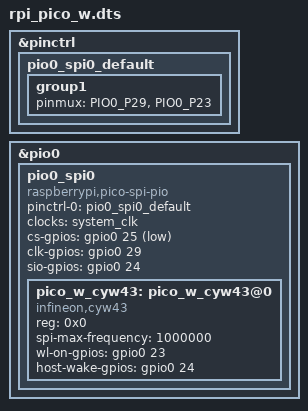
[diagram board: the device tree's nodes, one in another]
/*
 * Copyright (c) 2023 Dave Rensberger - Beechwoods Software
 *
 * SPDX-License-Identifier: Apache-2.0
 */

/dts-v1/;

#include "rpi_pico-common.dtsi"

&pinctrl {
	pio0_spi0_default: pio0_spi0_default {
	        /* gpio 25 is used for chip select, not assigned to the PIO */
		group1 {
			pinmux = <PIO0_P29>, <PIO0_P23>;
		};
	};

};

&pio0 {
 	status = "okay";

	pio0_spi0: pio0_spi0 {
		pinctrl-0 = <&pio0_spi0_default>;
		pinctrl-names = "default";

		compatible = "raspberrypi,pico-spi-pio";
		status = "okay";
		#address-cells = <1>;
		#size-cells = <0>;
		clocks = < &system_clk >;
        	cs-gpios = <&gpio0 25 GPIO_ACTIVE_LOW>;
		clk-gpios = <&gpio0 29 GPIO_ACTIVE_HIGH>;
		sio-gpios = <&gpio0 24 GPIO_ACTIVE_HIGH>;
		pico_w_cyw43: pico_w_cyw43@0 {
			compatible = "infineon,cyw43";
			reg = < 0x0 >;
			spi-max-frequency = < 1000000 >;
			wl-on-gpios = < &gpio0 23 GPIO_ACTIVE_HIGH >;
			host-wake-gpios = <&gpio0 24 GPIO_ACTIVE_HIGH>;	
		};
	};
};

